# STM32MP13xx register map
File version: 1.7
CPU: CA7 r0p0, little endian, MPU, FPU, 4 interrupt priority bits
Registers are 32-bit, read-write, reset 0x0 unless marked. A register's access mark holds for its fields unless they carry their own. Offsets are from the block's base; [hi:lo] are bit positions; 'fields as' and 'values as' point back to an identical list.

## USBPHYC
Base 0x5A006000
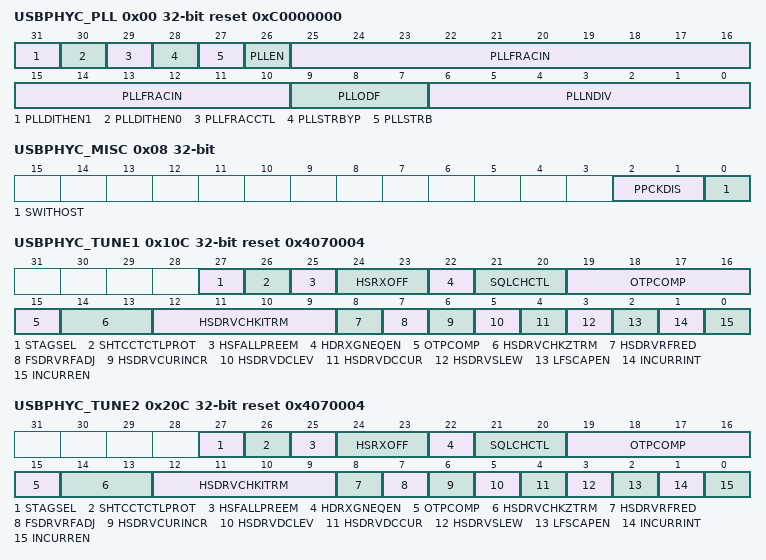
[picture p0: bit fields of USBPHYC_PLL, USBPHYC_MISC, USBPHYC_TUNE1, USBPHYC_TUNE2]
0x00 USBPHYC_PLL reset 0xC0000000 — USBPHYC PLL control register
  [31] PLLDITHEN1 — PLL dither 1 (rectangular) This bit enables the rectangular dither for the PLL.
    0=Enables the rectangular PDF dither input to SDM of PLL (not recommended); 1=Disables the rectangular PDF dither input to SDM of PLL
  [30] PLLDITHEN0 — PLL dither 2 (triangular) This bit enables the triangular dither for the PLL.
    0=Enables the triangular PDF dither input to SDM of PLL (not recommended); 1=Disables the triangular PDF dither input to SDM of PLL
  [29] PLLFRACCTL — PLL fractional mode control
    0=Fractional mode off; 1=Fractional mode on
  [28] PLLSTRBYP — PLL strobe bypass Bypass the strobe signal. If set to 1 before setting PLLEN=1, then the PLL will start up in fractional mode depending on the setting of PLLFRACCTL.
    0=Do not bypass the strobe signal; 1=Bypass the strobe signal
  [27] PLLSTRB — PLL strobe This bit allows to control an asynchronous strobe signal provided as an input to the fractional controller. A rising edge of PLLSTRB signal indicates to the fractional controller that a new fractional word is to be loaded.
    0=Strobe set to 0; 1=Strobe set to 1
  [26] PLLEN — PLL enable This bit enables the PLL.
    0=PLL disabled; 1=PLL enabled
  [25:10] PLLFRACIN — PLL fractional input PLLFRACIN is the fractional input of the PLL divider.
  [9:7] PLLODF — PLL output division factor
  [6:0] PLLNDIV — Loop division factor of PLL (integer part)
0x08 USBPHYC_MISC — USBPHYC misc control register
  [2:1] PPCKDIS — Intelligent per HS PHY port clock gating control This register is static.
    0=No clock gating. PHY dedicated 60 MHz Port1/Port2 clocks are always delivered to target controller. PHY 48 MHz output clock is always delivered to target controller.; 1=Intelligent clock gating for Port1. Port1 60 MHz input clock gated (Port1 is unused). Port2 dedicated 60 MHz is delivered in case of parallel data comm is requested on target controller (Host or OTG). PHY 48 MHz is delivered in case serial comm is requested on target controller (Host if SWITHOST = 1 else OTG).; 2=Intelligent clock gating for Port2. Port2 60 MHz input clock gated (Port2 is unused). Port1 dedicated 60 MHz is delivered in case of parallel data comm is requested on target controller (Host). PHY 48 MHz is delivered in case serial comm is requested on target controller (Host if SWITHOST = 1 else OTG).; 3=Intelligent clock gating for Port1 and Port2. Port1 dedicated 60 MHz is delivered in case of parallel data comm is requested on target (Host). Port2 dedicated 60 MHz is delivered in case of parallel data comm is requested on target (Host if SWITHOST = 1 else OTG). PHY 48 MHz output clock is delivered in case serial comm is requested on target controller (Host or OTG).
  [0] SWITHOST — Switch host Controls main switch connecting USB PHY 2nd port between USB host controller and USB OTG controller. This register is static.
    0=Select OTG controller for 2nd PHY port; 1=Select Host controller for 2nd PHY port
0x10C USBPHYC_TUNE1 reset 0x4070004 — USBPHYC PHY 1 TUNE register
  [27] STAGSEL — Staggering selection This bit enables the HS Tx staggering.
    0=Disable the basic staggering in HS Tx mode; 1=Enable the basic staggering in HS Tx mode
  [26] SHTCCTCTLPROT — Short circuit control protection This bit enables the short circuit protection circuitry in LS/FS driver.
    0=Short circuit protection disabled; 1=Short circuit protection enabled
  [25] HSFALLPREEM — HS fall time pre-emphasis This bit enables the HS fall time control of single ended signals during pre-emphasis:
    0=Control On; 1=Control Off
  [24:23] HSRXOFF — HS receiver offset adjustment
    0=No offset; 1=Offset +5 mV; 2=Offset +10 mV; 3=Offset -5 mV
  [22] HDRXGNEQEN — Enable HS Rx gain equalizer
    0=Disable the gain equalizer; 1=Enable the gain equalizer
  [21:20] SQLCHCTL — Squelch control This bitfield adjusts the squelch DC threshold value.
    0=No shift in threshold; 1=Squelch DC threshold shift by +7 mV; 2=Squelch DC threshold shift by -5 mV; 3=Squelch DC threshold shift by +14 mV
  [19:15] OTPCOMP — OTP compensation code
  [14:13] HSDRVCHKZTRM — HS driver choke impedance trim This bitfield controls the PHY bus HS driver impedance tuning for choke compensation.
    0=No impedance offset; 1=Reduce the impedance by 2 ohm; 2=Reduce the impedance by 4 ohm; 3=Reduce the impedance by 6 ohm
  [12:9] HSDRVCHKITRM — HS driver choke current trim This bitfield controls the HS driver current trimming pins for choke compensation.
    0=18.87 mA target current / nominal + 0%; 1=19.165 mA target current / nominal + 1.56%; 2=19.46 mA target current / nominal + 3.12%; 3=19.755 mA target current / nominal + 4.68%; 4=20.05 mA target current / nominal + 6.24%; 5=20.345 mA target current / nominal + 7.8%; 6=20.64 mA target current / nominal + 9.36%; 7=20.935 mA target current / nominal + 10.92%; 8=21.23 mA target current / nominal + 12.48%; 9=21.525 mA target current / nominal + 14.04%; 10=21.82 mA target current / nominal + 15.6%; 11=22.115 mA target current / nominal + 17.16%; 12=22.458 mA target current / nominal + 19.01%; 13=22.755 mA target current / nominal + 20.58%; 14=23.052 mA target current / nominal + 22.16%; 15=23.348 mA target current / nominal + 23.73%
  [8] HSDRVRFRED — High-speed rise-fall reduction enable
    0=Default rise/fall time; 1=Increases the rise/fall time by 20%
  [7] FSDRVRFADJ — Tuning pin to adjust the full speed rise/fall time
    0=Disables the full speed rise/fall tuning option; 1=Enables the full speed rise/fall tuning option
  [6] HSDRVCURINCR — Enable the HS driver current increase feature
    0=Disables the HSDRVDCLEV feature; 1=Enables the HSDRVDCLEV feature
  [5] HSDRVDCLEV — HS driver DC level This bit allows to increase the HS driver DC level. I is not applicable during the HS test J and test K data transfer.
    0=Increases the HS driver DC level by 5 to 7 mV if HSDRVCURINCR = '1'; 1=Increases the HS driver DC level by 10 to 14 mV if HSDRVCURINCR = '1'
  [4] HSDRVDCCUR — HS driver DC level This bit allows to decrease the HS driver DC level.
    0=Keeps the normal HS driver DC level; 1=Decreases the HS driver DC level by 5 to 7 mV
  [3] HSDRVSLEW — HS driver slew rate This bit controls the HS driver slew rate.
    0=Keeps the normal slew rate; 1=Slows the driver slew rate by 10%
  [2] LFSCAPEN — Low full speed enable This bit enables the low full speed feedback capacitor.
    0=Disables the feedback capacitor; 1=Enables the feedback capacitor
  [1] INCURRINT — Current boosting value This bit controls the PHY current boosting value.
    0=Provides a current boosting of 1mA if INCURREN = '1'; 1=Provides a current boosting of 2mA if INCURREN = '1'
  [0] INCURREN — The bit enables the current boosting function.
    0=Disables the current boosting; 1=Enables the current boosting
0x20C USBPHYC_TUNE2 reset 0x4070004 — USBPHYC PHY 2 TUNE register
  fields as USBPHYC_TUNE1
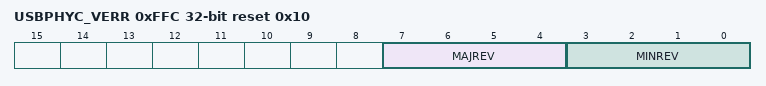
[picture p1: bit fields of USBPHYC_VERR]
0xFFC USBPHYC_VERR ro reset 0x10 — USBPHYC VERSION register
  [7:4] MAJREV — Major revision
  [3:0] MINREV — Minor revision
